# STM32L452 register map
File version: 1.0
CPU: CM4 r0p1, little endian, MPU, FPU, 4 interrupt priority bits
Registers are 32-bit, read-write, reset 0x0 unless marked. A register's access mark holds for its fields unless they carry their own. Offsets are from the block's base; [hi:lo] are bit positions; {n}, {i} and the like mark numbered series; 'fields as' and 'values as' point back to an identical list.

## DMA1 — Direct memory access controller
Base 0x40020000
Same registers: DMA2 0x40020400
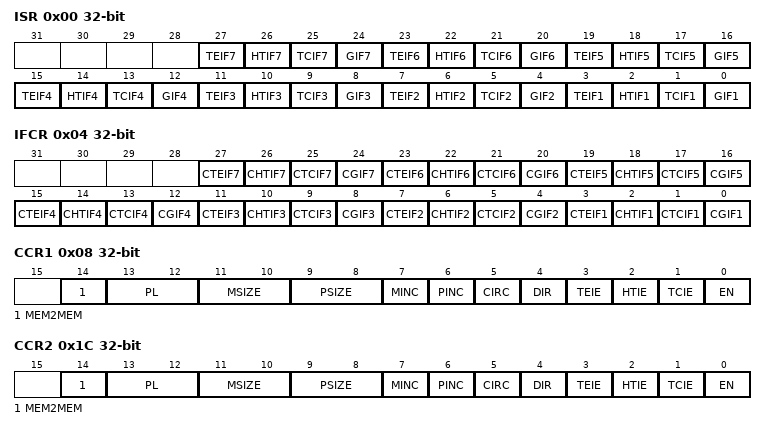
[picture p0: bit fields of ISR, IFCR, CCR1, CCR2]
0x00 ISR ro — interrupt status register
  [4n-1] TEIF{n} (n=1..7) — Channel x transfer error flag (x = 1 ..7)
  [4n-2] HTIF{n} (n=1..7) — Channel x half transfer flag (x = 1 ..7)
  [4n-3] TCIF{n} (n=1..7) — Channel x transfer complete flag (x = 1 ..7)
  [4n-4] GIF{n} (n=1..7) — Channel x global interrupt flag (x = 1 ..7)
0x04 IFCR wo — interrupt flag clear register
  [4n-1] CTEIF{n} (n=1..7) — Channel x transfer error clear (x = 1 ..7)
  [4n-2] CHTIF{n} (n=1..7) — Channel x half transfer clear (x = 1 ..7)
  [4n-3] CTCIF{n} (n=1..7) — Channel x transfer complete clear (x = 1 ..7)
  [4n-4] CGIF{n} (n=1..7) — Channel x global interrupt clear (x = 1 ..7)
0x08 CCR1 — channel x configuration register
  [14] MEM2MEM — Memory to memory mode
  [13:12] PL — Channel priority level
  [11:10] MSIZE — Memory size
  [9:8] PSIZE — Peripheral size
  [7] MINC — Memory increment mode
  [6] PINC — Peripheral increment mode
  [5] CIRC — Circular mode
  [4] DIR — Data transfer direction
  [3] TEIE — Transfer error interrupt enable
  [2] HTIE — Half transfer interrupt enable
  [1] TCIE — Transfer complete interrupt enable
  [0] EN — Channel enable
0x0C CNDTR1 — channel x number of data register
  [15:0] NDT — Number of data to transfer
0x10 CPAR1 — channel x peripheral address register
  [31:0] PA — Peripheral address
{0x0+0x14*i} CMAR{i} (i=1..7) — channel x memory address register
  [31:0] MA — Memory address
0x1C CCR2 — channel x configuration register
  fields as CCR1
0x20 CNDTR2 — channel x number of data register
  [15:0] NDT — Number of data to transfer
0x24 CPAR2 — channel x peripheral address register
  [31:0] PA — Peripheral address
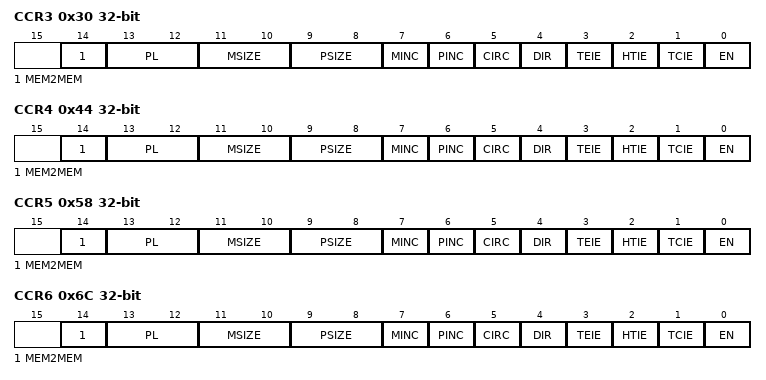
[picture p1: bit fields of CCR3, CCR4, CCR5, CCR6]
0x30 CCR3 — channel x configuration register
  fields as CCR1
0x34 CNDTR3 — channel x number of data register
  [15:0] NDT — Number of data to transfer
0x38 CPAR3 — channel x peripheral address register
  [31:0] PA — Peripheral address
0x44 CCR4 — channel x configuration register
  fields as CCR1
0x48 CNDTR4 — channel x number of data register
  [15:0] NDT — Number of data to transfer
0x4C CPAR4 — channel x peripheral address register
  [31:0] PA — Peripheral address
0x58 CCR5 — channel x configuration register
  fields as CCR1
0x5C CNDTR5 — channel x number of data register
  [15:0] NDT — Number of data to transfer
0x60 CPAR5 — channel x peripheral address register
  [31:0] PA — Peripheral address
0x6C CCR6 — channel x configuration register
  fields as CCR1
0x70 CNDTR6 — channel x number of data register
  [15:0] NDT — Number of data to transfer
0x74 CPAR6 — channel x peripheral address register
  [31:0] PA — Peripheral address
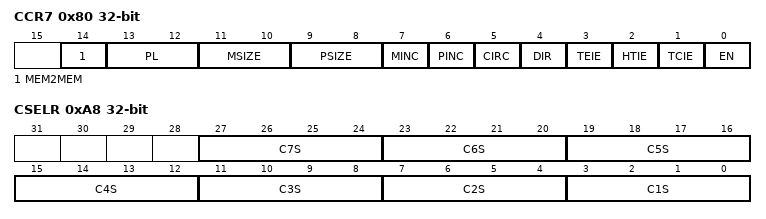
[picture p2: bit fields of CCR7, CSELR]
0x80 CCR7 — channel x configuration register
  fields as CCR1
0x84 CNDTR7 — channel x number of data register
  [15:0] NDT — Number of data to transfer
0x88 CPAR7 — channel x peripheral address register
  [31:0] PA — Peripheral address
0xA8 CSELR — channel selection register
  [4n-1:4n-4] C{n}S (n=1..7) — DMA channel {n} selection

## CRC — Cyclic redundancy check calculation unit
Base 0x40023000
0x00 DR reset 0xFFFFFFFF — Data register
  [31:0] DR — Data register bits
0x04 IDR — Independent data register
  [7:0] IDR — General-purpose 8-bit data register bits
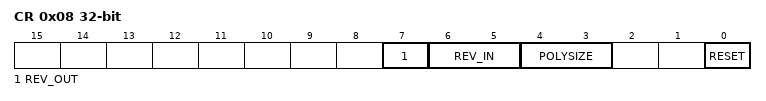
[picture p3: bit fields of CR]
0x08 CR access per field — Control register
  [7] REV_OUT rw — Reverse output data
  [6:5] REV_IN rw — Reverse input data
  [4:3] POLYSIZE rw — Polynomial size
  [0] RESET wo — RESET bit
0x10 INIT reset 0xFFFFFFFF — Initial CRC value
  [31:0] CRC_INIT — Programmable initial CRC value
0x14 POL reset 0x4C11DB7 — polynomial
  [31:0] Polynomialcoefficients — Programmable polynomial

## Notices in the file
Copyright (c) 2024 STMicroelectronics.
SPDX-License-Identifier: Apache-2.0
Licensed under the Apache License, Version 2.0 (the "License");
you may not use this file except in compliance with the License.
You may obtain a copy of the License at
http://www.apache.org/licenses/LICENSE-2.0
Unless required by applicable law or agreed to in writing, software
distributed under the License is distributed on an "AS IS" BASIS,
WITHOUT WARRANTIES OR CONDITIONS OF ANY KIND, either express or implied.
See the License for the specific language governing permissions and
limitations under the License.
